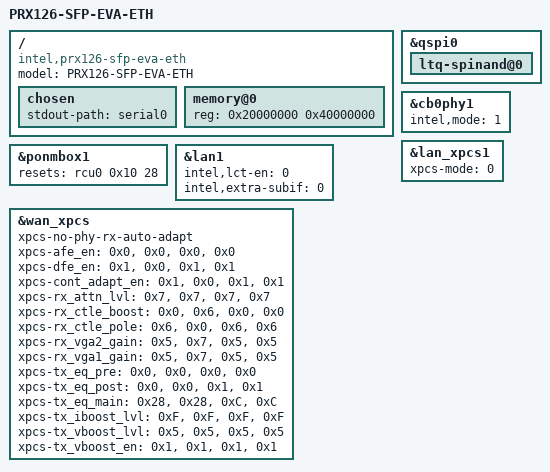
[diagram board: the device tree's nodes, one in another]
/dts-v1/;
#include <dt-bindings/interrupt-controller/mips-gic.h>
#include <dt-bindings/clock/intel,prx300-clk.h>
#include <dt-bindings/pinctrl/intel,equilibrium.h>
#include "prx300.dtsi"
#include "prx126-sfp-eva.dtsi"

/ {
	model = "PRX126-SFP-EVA-ETH";
	compatible = "intel,prx126-sfp-eva-eth", "intel,prx126-eva", "intel,prx300";

	chosen {
		stdout-path = "serial0";
	};

	memory@0 {
		device_type = "memory";
		reg = <0x20000000 0x40000000>; /* 1024 MB */
	};
};

&ponmbox1 {
	status = "okay";
	resets = <&rcu0 0x10 28>;
	reset-names = "ponip";
	/delete-property/ pinctrl-names;
	/delete-property/ pinctrl-0;
};

&lan1 {
	intel,lct-en = <0>;
	intel,extra-subif = <0>;
};

&qspi0 {
	status = "okay";
	ltq-spinand@0 {
		status = "okay";
	};
};

&cb0phy1 {
	intel,mode = <1>; /*0-pcie, 1-xpcs*/
	status = "okay";
};

&lan_xpcs1 {
	status = "okay";
	xpcs-mode = <0>; /* 0 - 10G_KR_MODE, 1 - 10G_XAUI_MODE, 2 - 1G_XAUI_MODE, 3 - 2P5G_GMII_MODE */
};

&wan_xpcs {
	status = "okay";
	xpcs-no-phy-rx-auto-adapt; /* <2dB loss PHY adapt not needed*/
	/* xpcs RX EQ Settings */
	xpcs-afe_en = <0x0>, <0x0>, <0x0>, <0x0>;
	xpcs-dfe_en = <0x1>, <0x0>, <0x1>, <0x1>;
	xpcs-cont_adapt_en = <0x1>, <0x0>, <0x1>, <0x1>;
	xpcs-rx_attn_lvl = <0x7>, <0x7>, <0x7>, <0x7>;
	xpcs-rx_ctle_boost = <0x0>, <0x6>, <0x0>, <0x0>;
	xpcs-rx_ctle_pole = <0x6>, <0x0>, <0x6>, <0x6>;
	xpcs-rx_vga2_gain = <0x5>, <0x7>, <0x5>, <0x5>;
	xpcs-rx_vga1_gain = <0x5>, <0x7>, <0x5>, <0x5>;
	/* xpcs TX EQ Settings */
	xpcs-tx_eq_pre = <0x0>, <0x0>, <0x0>, <0x0>;
	xpcs-tx_eq_post =  <0x0>, <0x0>, <0x1>, <0x1>;
	xpcs-tx_eq_main = <0x28>, <0x28>, <0xC>, <0xC>;
	xpcs-tx_iboost_lvl = <0xF>, <0xF>,<0xF>, <0xF>;
	xpcs-tx_vboost_lvl = <0x5>, <0x5>, <0x5>, <0x5>;
	xpcs-tx_vboost_en = <0x1>, <0x1>, <0x1>, <0x1>;
};
